# F28x7x_pie_ctrl_regs register map
Vendor: Texas Instruments
Peripheral module from a debugger description file (folder C2000).
Address unit: 16 bits
Registers are 16-bit, read-write, no defined reset value unless marked. A register's access mark holds for its fields unless they carry their own. Offsets are as the file gives them; lines under a group give offsets from that group; [hi:lo] are bit positions; {n}, {i} and the like mark numbered series; 'fields as' and 'values as' point back to an identical list; <NAME> marks a mode.

## PIE_CTRL_REGS
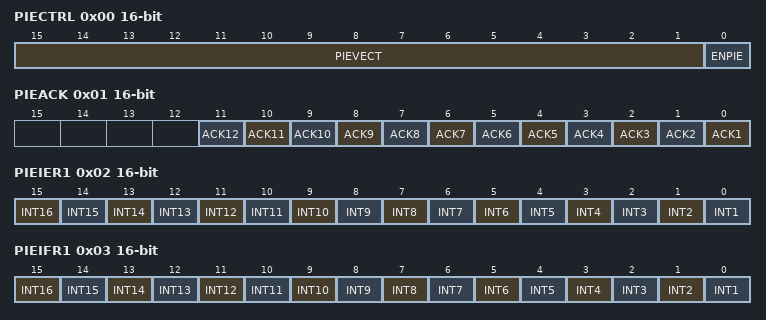
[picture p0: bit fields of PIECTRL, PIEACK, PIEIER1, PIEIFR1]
0x00 PIECTRL — Control Register
  [15:1] PIEVECT — PIE Vector Address
  [0] ENPIE — PIE Enable
0x01 PIEACK — Acknowledge Register
  [n-1] ACK{n} (n=1..12) — Acknowledge PIE Interrupt Group {n}
0x02 PIEIER1 — INT1 Group Enable Register
  [15] INT16 — Interrupt Enable for INT1.16
  [14] INT15 — Interrupt Enable for INT1.15
  [13] INT14 — Interrupt Enable for INT1.14
  [12] INT13 — Interrupt Enable for INT1.13
  [11] INT12 — Interrupt Enable for INT1.12
  [10] INT11 — Interrupt Enable for INT1.11
  [9] INT10 — Interrupt Enable for INT1.10
  [8] INT9 — Interrupt Enable for INT1.9
  [7] INT8 — Interrupt Enable for INT1.8
  [6] INT7 — Interrupt Enable for INT1.7
  [5] INT6 — Interrupt Enable for INT1.6
  [4] INT5 — Interrupt Enable for INT1.5
  [3] INT4 — Interrupt Enable for INT1.4
  [2] INT3 — Interrupt Enable for INT1.3
  [1] INT2 — Interrupt Enable for INT1.2
  [0] INT1 — Interrupt Enable for INT1.1
0x03 PIEIFR1 — INT1 Group Flag Register
  [15] INT16 — Interrupt Flag for INT1.16
  [14] INT15 — Interrupt Flag for INT1.15
  [13] INT14 — Interrupt Flag for INT1.14
  [12] INT13 — Interrupt Flag for INT1.13
  [11] INT12 — Interrupt Flag for INT1.12
  [10] INT11 — Interrupt Flag for INT1.11
  [9] INT10 — Interrupt Flag for INT1.10
  [8] INT9 — Interrupt Flag for INT1.9
  [7] INT8 — Interrupt Flag for INT1.8
  [6] INT7 — Interrupt Flag for INT1.7
  [5] INT6 — Interrupt Flag for INT1.6
  [4] INT5 — Interrupt Flag for INT1.5
  [3] INT4 — Interrupt Flag for INT1.4
  [2] INT3 — Interrupt Flag for INT1.3
  [1] INT2 — Interrupt Flag for INT1.2
  [0] INT1 — Interrupt Flag for INT1.1
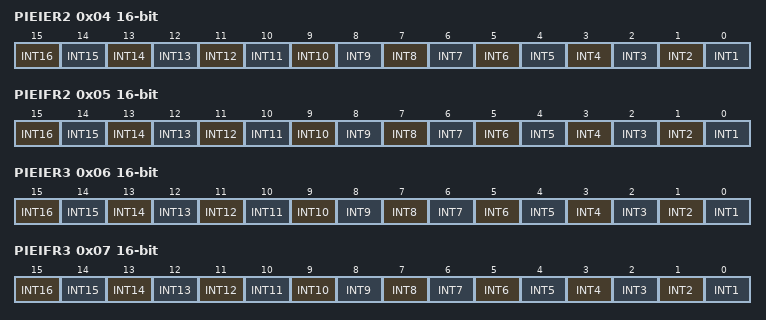
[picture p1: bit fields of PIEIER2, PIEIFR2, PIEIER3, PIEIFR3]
0x04 PIEIER2 — INT2 Group Enable Register
  [15] INT16 — Interrupt Enable for INT2.16
  [14] INT15 — Interrupt Enable for INT2.15
  [13] INT14 — Interrupt Enable for INT2.14
  [12] INT13 — Interrupt Enable for INT2.13
  [11] INT12 — Interrupt Enable for INT2.12
  [10] INT11 — Interrupt Enable for INT2.11
  [9] INT10 — Interrupt Enable for INT2.10
  [8] INT9 — Interrupt Enable for INT2.9
  [7] INT8 — Interrupt Enable for INT2.8
  [6] INT7 — Interrupt Enable for INT2.7
  [5] INT6 — Interrupt Enable for INT2.6
  [4] INT5 — Interrupt Enable for INT2.5
  [3] INT4 — Interrupt Enable for INT2.4
  [2] INT3 — Interrupt Enable for INT2.3
  [1] INT2 — Interrupt Enable for INT2.2
  [0] INT1 — Interrupt Enable for INT2.1
0x05 PIEIFR2 — INT2 Group Flag Register
  [15] INT16 — Interrupt Flag for INT2.16
  [14] INT15 — Interrupt Flag for INT2.15
  [13] INT14 — Interrupt Flag for INT2.14
  [12] INT13 — Interrupt Flag for INT2.13
  [11] INT12 — Interrupt Flag for INT2.12
  [10] INT11 — Interrupt Flag for INT2.11
  [9] INT10 — Interrupt Flag for INT2.10
  [8] INT9 — Interrupt Flag for INT2.9
  [7] INT8 — Interrupt Flag for INT2.8
  [6] INT7 — Interrupt Flag for INT2.7
  [5] INT6 — Interrupt Flag for INT2.6
  [4] INT5 — Interrupt Flag for INT2.5
  [3] INT4 — Interrupt Flag for INT2.4
  [2] INT3 — Interrupt Flag for INT2.3
  [1] INT2 — Interrupt Flag for INT2.2
  [0] INT1 — Interrupt Flag for INT2.1
0x06 PIEIER3 — INT3 Group Enable Register
  [15] INT16 — Interrupt Enable for INT3.16
  [14] INT15 — Interrupt Enable for INT3.15
  [13] INT14 — Interrupt Enable for INT3.14
  [12] INT13 — Interrupt Enable for INT3.13
  [11] INT12 — Interrupt Enable for INT3.12
  [10] INT11 — Interrupt Enable for INT3.11
  [9] INT10 — Interrupt Enable for INT3.10
  [8] INT9 — Interrupt Enable for INT3.9
  [7] INT8 — Interrupt Enable for INT3.8
  [6] INT7 — Interrupt Enable for INT3.7
  [5] INT6 — Interrupt Enable for INT3.6
  [4] INT5 — Interrupt Enable for INT3.5
  [3] INT4 — Interrupt Enable for INT3.4
  [2] INT3 — Interrupt Enable for INT3.3
  [1] INT2 — Interrupt Enable for INT3.2
  [0] INT1 — Interrupt Enable for INT3.1
0x07 PIEIFR3 — INT3 Group Flag Register
  [15] INT16 — Interrupt Flag for INT3.16
  [14] INT15 — Interrupt Flag for INT3.15
  [13] INT14 — Interrupt Flag for INT3.14
  [12] INT13 — Interrupt Flag for INT3.13
  [11] INT12 — Interrupt Flag for INT3.12
  [10] INT11 — Interrupt Flag for INT3.11
  [9] INT10 — Interrupt Flag for INT3.10
  [8] INT9 — Interrupt Flag for INT3.9
  [7] INT8 — Interrupt Flag for INT3.8
  [6] INT7 — Interrupt Flag for INT3.7
  [5] INT6 — Interrupt Flag for INT3.6
  [4] INT5 — Interrupt Flag for INT3.5
  [3] INT4 — Interrupt Flag for INT3.4
  [2] INT3 — Interrupt Flag for INT3.3
  [1] INT2 — Interrupt Flag for INT3.2
  [0] INT1 — Interrupt Flag for INT3.1
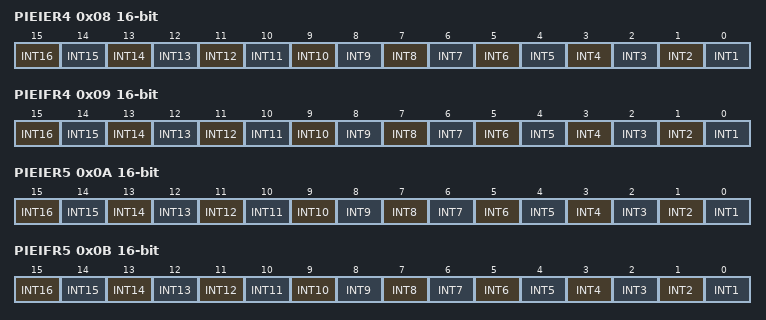
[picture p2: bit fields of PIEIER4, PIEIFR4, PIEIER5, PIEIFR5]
0x08 PIEIER4 — INT4 Group Enable Register
  [15] INT16 — Interrupt Enable for INT4.16
  [14] INT15 — Interrupt Enable for INT4.15
  [13] INT14 — Interrupt Enable for INT4.14
  [12] INT13 — Interrupt Enable for INT4.13
  [11] INT12 — Interrupt Enable for INT4.12
  [10] INT11 — Interrupt Enable for INT4.11
  [9] INT10 — Interrupt Enable for INT4.10
  [8] INT9 — Interrupt Enable for INT4.9
  [7] INT8 — Interrupt Enable for INT4.8
  [6] INT7 — Interrupt Enable for INT4.7
  [5] INT6 — Interrupt Enable for INT4.6
  [4] INT5 — Interrupt Enable for INT4.5
  [3] INT4 — Interrupt Enable for INT4.4
  [2] INT3 — Interrupt Enable for INT4.3
  [1] INT2 — Interrupt Enable for INT4.2
  [0] INT1 — Interrupt Enable for INT4.1
0x09 PIEIFR4 — INT4 Group Flag Register
  [15] INT16 — Interrupt Flag for INT4.16
  [14] INT15 — Interrupt Flag for INT4.15
  [13] INT14 — Interrupt Flag for INT4.14
  [12] INT13 — Interrupt Flag for INT4.13
  [11] INT12 — Interrupt Flag for INT4.12
  [10] INT11 — Interrupt Flag for INT4.11
  [9] INT10 — Interrupt Flag for INT4.10
  [8] INT9 — Interrupt Flag for INT4.9
  [7] INT8 — Interrupt Flag for INT4.8
  [6] INT7 — Interrupt Flag for INT4.7
  [5] INT6 — Interrupt Flag for INT4.6
  [4] INT5 — Interrupt Flag for INT4.5
  [3] INT4 — Interrupt Flag for INT4.4
  [2] INT3 — Interrupt Flag for INT4.3
  [1] INT2 — Interrupt Flag for INT4.2
  [0] INT1 — Interrupt Flag for INT4.1
0x0A PIEIER5 — INT5 Group Enable Register
  [15] INT16 — Interrupt Enable for INT5.16
  [14] INT15 — Interrupt Enable for INT5.15
  [13] INT14 — Interrupt Enable for INT5.14
  [12] INT13 — Interrupt Enable for INT5.13
  [11] INT12 — Interrupt Enable for INT5.12
  [10] INT11 — Interrupt Enable for INT5.11
  [9] INT10 — Interrupt Enable for INT5.10
  [8] INT9 — Interrupt Enable for INT5.9
  [7] INT8 — Interrupt Enable for INT5.8
  [6] INT7 — Interrupt Enable for INT5.7
  [5] INT6 — Interrupt Enable for INT5.6
  [4] INT5 — Interrupt Enable for INT5.5
  [3] INT4 — Interrupt Enable for INT5.4
  [2] INT3 — Interrupt Enable for INT5.3
  [1] INT2 — Interrupt Enable for INT5.2
  [0] INT1 — Interrupt Enable for INT5.1
0x0B PIEIFR5 — INT5 Group Flag Register
  [15] INT16 — Interrupt Flag for INT5.16
  [14] INT15 — Interrupt Flag for INT5.15
  [13] INT14 — Interrupt Flag for INT5.14
  [12] INT13 — Interrupt Flag for INT5.13
  [11] INT12 — Interrupt Flag for INT5.12
  [10] INT11 — Interrupt Flag for INT5.11
  [9] INT10 — Interrupt Flag for INT5.10
  [8] INT9 — Interrupt Flag for INT5.9
  [7] INT8 — Interrupt Flag for INT5.8
  [6] INT7 — Interrupt Flag for INT5.7
  [5] INT6 — Interrupt Flag for INT5.6
  [4] INT5 — Interrupt Flag for INT5.5
  [3] INT4 — Interrupt Flag for INT5.4
  [2] INT3 — Interrupt Flag for INT5.3
  [1] INT2 — Interrupt Flag for INT5.2
  [0] INT1 — Interrupt Flag for INT5.1
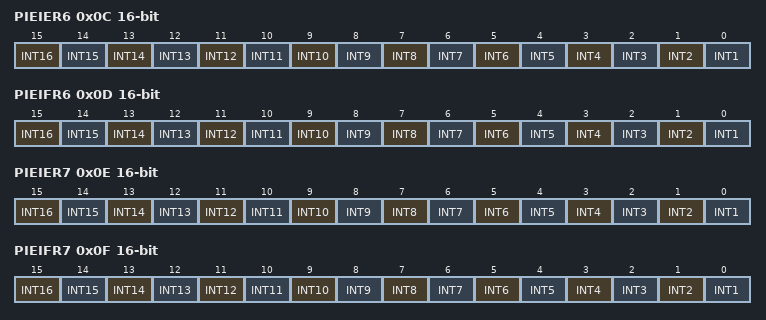
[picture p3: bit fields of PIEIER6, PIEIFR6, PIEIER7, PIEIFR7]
0x0C PIEIER6 — INT6 Group Enable Register
  [15] INT16 — Interrupt Enable for INT6.16
  [14] INT15 — Interrupt Enable for INT6.15
  [13] INT14 — Interrupt Enable for INT6.14
  [12] INT13 — Interrupt Enable for INT6.13
  [11] INT12 — Interrupt Enable for INT6.12
  [10] INT11 — Interrupt Enable for INT6.11
  [9] INT10 — Interrupt Enable for INT6.10
  [8] INT9 — Interrupt Enable for INT6.9
  [7] INT8 — Interrupt Enable for INT6.8
  [6] INT7 — Interrupt Enable for INT6.7
  [5] INT6 — Interrupt Enable for INT6.6
  [4] INT5 — Interrupt Enable for INT6.5
  [3] INT4 — Interrupt Enable for INT6.4
  [2] INT3 — Interrupt Enable for INT6.3
  [1] INT2 — Interrupt Enable for INT6.2
  [0] INT1 — Interrupt Enable for INT6.1
0x0D PIEIFR6 — INT6 Group Flag Register
  [15] INT16 — Interrupt Flag for INT6.16
  [14] INT15 — Interrupt Flag for INT6.15
  [13] INT14 — Interrupt Flag for INT6.14
  [12] INT13 — Interrupt Flag for INT6.13
  [11] INT12 — Interrupt Flag for INT6.12
  [10] INT11 — Interrupt Flag for INT6.11
  [9] INT10 — Interrupt Flag for INT6.10
  [8] INT9 — Interrupt Flag for INT6.9
  [7] INT8 — Interrupt Flag for INT6.8
  [6] INT7 — Interrupt Flag for INT6.7
  [5] INT6 — Interrupt Flag for INT6.6
  [4] INT5 — Interrupt Flag for INT6.5
  [3] INT4 — Interrupt Flag for INT6.4
  [2] INT3 — Interrupt Flag for INT6.3
  [1] INT2 — Interrupt Flag for INT6.2
  [0] INT1 — Interrupt Flag for INT6.1
0x0E PIEIER7 — INT7 Group Enable Register
  [15] INT16 — Interrupt Enable for INT7.16
  [14] INT15 — Interrupt Enable for INT7.15
  [13] INT14 — Interrupt Enable for INT7.14
  [12] INT13 — Interrupt Enable for INT7.13
  [11] INT12 — Interrupt Enable for INT7.12
  [10] INT11 — Interrupt Enable for INT7.11
  [9] INT10 — Interrupt Enable for INT7.10
  [8] INT9 — Interrupt Enable for INT7.9
  [7] INT8 — Interrupt Enable for INT7.8
  [6] INT7 — Interrupt Enable for INT7.7
  [5] INT6 — Interrupt Enable for INT7.6
  [4] INT5 — Interrupt Enable for INT7.5
  [3] INT4 — Interrupt Enable for INT7.4
  [2] INT3 — Interrupt Enable for INT7.3
  [1] INT2 — Interrupt Enable for INT7.2
  [0] INT1 — Interrupt Enable for INT7.1
0x0F PIEIFR7 — INT7 Group Flag Register
  [15] INT16 — Interrupt Flag for INT7.16
  [14] INT15 — Interrupt Flag for INT7.15
  [13] INT14 — Interrupt Flag for INT7.14
  [12] INT13 — Interrupt Flag for INT7.13
  [11] INT12 — Interrupt Flag for INT7.12
  [10] INT11 — Interrupt Flag for INT7.11
  [9] INT10 — Interrupt Flag for INT7.10
  [8] INT9 — Interrupt Flag for INT7.9
  [7] INT8 — Interrupt Flag for INT7.8
  [6] INT7 — Interrupt Flag for INT7.7
  [5] INT6 — Interrupt Flag for INT7.6
  [4] INT5 — Interrupt Flag for INT7.5
  [3] INT4 — Interrupt Flag for INT7.4
  [2] INT3 — Interrupt Flag for INT7.3
  [1] INT2 — Interrupt Flag for INT7.2
  [0] INT1 — Interrupt Flag for INT7.1
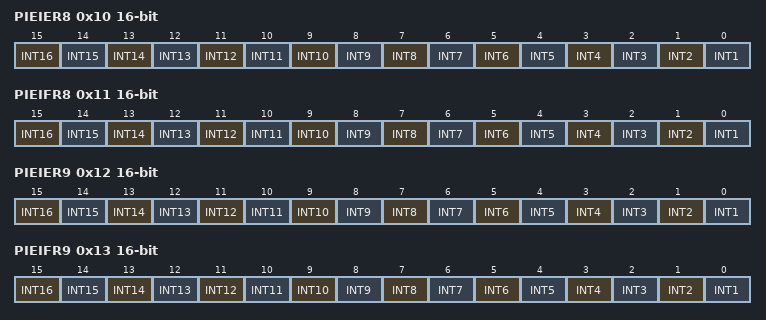
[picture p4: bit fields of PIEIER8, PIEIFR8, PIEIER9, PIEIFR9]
0x10 PIEIER8 — INT8 Group Enable Register
  [15] INT16 — Interrupt Enable for INT8.16
  [14] INT15 — Interrupt Enable for INT8.15
  [13] INT14 — Interrupt Enable for INT8.14
  [12] INT13 — Interrupt Enable for INT8.13
  [11] INT12 — Interrupt Enable for INT8.12
  [10] INT11 — Interrupt Enable for INT8.11
  [9] INT10 — Interrupt Enable for INT8.10
  [8] INT9 — Interrupt Enable for INT8.9
  [7] INT8 — Interrupt Enable for INT8.8
  [6] INT7 — Interrupt Enable for INT8.7
  [5] INT6 — Interrupt Enable for INT8.6
  [4] INT5 — Interrupt Enable for INT8.5
  [3] INT4 — Interrupt Enable for INT8.4
  [2] INT3 — Interrupt Enable for INT8.3
  [1] INT2 — Interrupt Enable for INT8.2
  [0] INT1 — Interrupt Enable for INT8.1
0x11 PIEIFR8 — INT8 Group Flag Register
  [15] INT16 — Interrupt Flag for INT8.16
  [14] INT15 — Interrupt Flag for INT8.15
  [13] INT14 — Interrupt Flag for INT8.14
  [12] INT13 — Interrupt Flag for INT8.13
  [11] INT12 — Interrupt Flag for INT8.12
  [10] INT11 — Interrupt Flag for INT8.11
  [9] INT10 — Interrupt Flag for INT8.10
  [8] INT9 — Interrupt Flag for INT8.9
  [7] INT8 — Interrupt Flag for INT8.8
  [6] INT7 — Interrupt Flag for INT8.7
  [5] INT6 — Interrupt Flag for INT8.6
  [4] INT5 — Interrupt Flag for INT8.5
  [3] INT4 — Interrupt Flag for INT8.4
  [2] INT3 — Interrupt Flag for INT8.3
  [1] INT2 — Interrupt Flag for INT8.2
  [0] INT1 — Interrupt Flag for INT8.1
0x12 PIEIER9 — INT9 Group Enable Register
  [15] INT16 — Interrupt Enable for INT9.16
  [14] INT15 — Interrupt Enable for INT9.15
  [13] INT14 — Interrupt Enable for INT9.14
  [12] INT13 — Interrupt Enable for INT9.13
  [11] INT12 — Interrupt Enable for INT9.12
  [10] INT11 — Interrupt Enable for INT9.11
  [9] INT10 — Interrupt Enable for INT9.10
  [8] INT9 — Interrupt Enable for INT9.9
  [7] INT8 — Interrupt Enable for INT9.8
  [6] INT7 — Interrupt Enable for INT9.7
  [5] INT6 — Interrupt Enable for INT9.6
  [4] INT5 — Interrupt Enable for INT9.5
  [3] INT4 — Interrupt Enable for INT9.4
  [2] INT3 — Interrupt Enable for INT9.3
  [1] INT2 — Interrupt Enable for INT9.2
  [0] INT1 — Interrupt Enable for INT9.1
0x13 PIEIFR9 — INT9 Group Flag Register
  [15] INT16 — Interrupt Flag for INT9.16
  [14] INT15 — Interrupt Flag for INT9.15
  [13] INT14 — Interrupt Flag for INT9.14
  [12] INT13 — Interrupt Flag for INT9.13
  [11] INT12 — Interrupt Flag for INT9.12
  [10] INT11 — Interrupt Flag for INT9.11
  [9] INT10 — Interrupt Flag for INT9.10
  [8] INT9 — Interrupt Flag for INT9.9
  [7] INT8 — Interrupt Flag for INT9.8
  [6] INT7 — Interrupt Flag for INT9.7
  [5] INT6 — Interrupt Flag for INT9.6
  [4] INT5 — Interrupt Flag for INT9.5
  [3] INT4 — Interrupt Flag for INT9.4
  [2] INT3 — Interrupt Flag for INT9.3
  [1] INT2 — Interrupt Flag for INT9.2
  [0] INT1 — Interrupt Flag for INT9.1
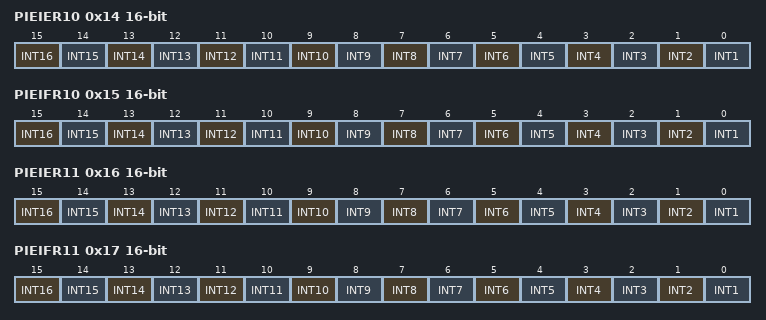
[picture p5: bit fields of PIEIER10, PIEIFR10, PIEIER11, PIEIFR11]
0x14 PIEIER10 — INT10 Group Enable Register
  [15] INT16 — Interrupt Enable for INT10.16
  [14] INT15 — Interrupt Enable for INT10.15
  [13] INT14 — Interrupt Enable for INT10.14
  [12] INT13 — Interrupt Enable for INT10.13
  [11] INT12 — Interrupt Enable for INT10.12
  [10] INT11 — Interrupt Enable for INT10.11
  [9] INT10 — Interrupt Enable for INT10.10
  [8] INT9 — Interrupt Enable for INT10.9
  [7] INT8 — Interrupt Enable for INT10.8
  [6] INT7 — Interrupt Enable for INT10.7
  [5] INT6 — Interrupt Enable for INT10.6
  [4] INT5 — Interrupt Enable for INT10.5
  [3] INT4 — Interrupt Enable for INT10.4
  [2] INT3 — Interrupt Enable for INT10.3
  [1] INT2 — Interrupt Enable for INT10.2
  [0] INT1 — Interrupt Enable for INT10.1
0x15 PIEIFR10 — INT10 Group Flag Register
  [15] INT16 — Interrupt Flag for INT10.16
  [14] INT15 — Interrupt Flag for INT10.15
  [13] INT14 — Interrupt Flag for INT10.14
  [12] INT13 — Interrupt Flag for INT10.13
  [11] INT12 — Interrupt Flag for INT10.12
  [10] INT11 — Interrupt Flag for INT10.11
  [9] INT10 — Interrupt Flag for INT10.10
  [8] INT9 — Interrupt Flag for INT10.9
  [7] INT8 — Interrupt Flag for INT10.8
  [6] INT7 — Interrupt Flag for INT10.7
  [5] INT6 — Interrupt Flag for INT10.6
  [4] INT5 — Interrupt Flag for INT10.5
  [3] INT4 — Interrupt Flag for INT10.4
  [2] INT3 — Interrupt Flag for INT10.3
  [1] INT2 — Interrupt Flag for INT10.2
  [0] INT1 — Interrupt Flag for INT10.1
0x16 PIEIER11 — INT11 Group Enable Register
  [15] INT16 — Interrupt Enable for INT11.16
  [14] INT15 — Interrupt Enable for INT11.15
  [13] INT14 — Interrupt Enable for INT11.14
  [12] INT13 — Interrupt Enable for INT11.13
  [11] INT12 — Interrupt Enable for INT11.12
  [10] INT11 — Interrupt Enable for INT11.11
  [9] INT10 — Interrupt Enable for INT11.10
  [8] INT9 — Interrupt Enable for INT11.9
  [7] INT8 — Interrupt Enable for INT11.8
  [6] INT7 — Interrupt Enable for INT11.7
  [5] INT6 — Interrupt Enable for INT11.6
  [4] INT5 — Interrupt Enable for INT11.5
  [3] INT4 — Interrupt Enable for INT11.4
  [2] INT3 — Interrupt Enable for INT11.3
  [1] INT2 — Interrupt Enable for INT11.2
  [0] INT1 — Interrupt Enable for INT11.1
0x17 PIEIFR11 — INT11 Group Flag Register
  [15] INT16 — Interrupt Flag for INT11.16
  [14] INT15 — Interrupt Flag for INT11.15
  [13] INT14 — Interrupt Flag for INT11.14
  [12] INT13 — Interrupt Flag for INT11.13
  [11] INT12 — Interrupt Flag for INT11.12
  [10] INT11 — Interrupt Flag for INT11.11
  [9] INT10 — Interrupt Flag for INT11.10
  [8] INT9 — Interrupt Flag for INT11.9
  [7] INT8 — Interrupt Flag for INT11.8
  [6] INT7 — Interrupt Flag for INT11.7
  [5] INT6 — Interrupt Flag for INT11.6
  [4] INT5 — Interrupt Flag for INT11.5
  [3] INT4 — Interrupt Flag for INT11.4
  [2] INT3 — Interrupt Flag for INT11.3
  [1] INT2 — Interrupt Flag for INT11.2
  [0] INT1 — Interrupt Flag for INT11.1
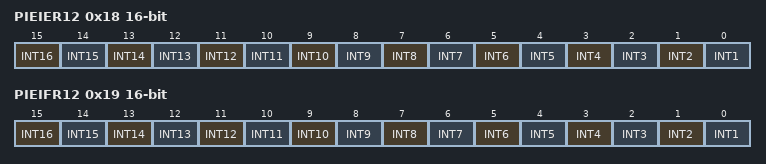
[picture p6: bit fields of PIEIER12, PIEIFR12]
0x18 PIEIER12 — INT12 Group Enable Register
  [15] INT16 — Interrupt Enable for INT12.16
  [14] INT15 — Interrupt Enable for INT12.15
  [13] INT14 — Interrupt Enable for INT12.14
  [12] INT13 — Interrupt Enable for INT12.13
  [11] INT12 — Interrupt Enable for INT12.12
  [10] INT11 — Interrupt Enable for INT12.11
  [9] INT10 — Interrupt Enable for INT12.10
  [8] INT9 — Interrupt Enable for INT12.9
  [7] INT8 — Interrupt Enable for INT12.8
  [6] INT7 — Interrupt Enable for INT12.7
  [5] INT6 — Interrupt Enable for INT12.6
  [4] INT5 — Interrupt Enable for INT12.5
  [3] INT4 — Interrupt Enable for INT12.4
  [2] INT3 — Interrupt Enable for INT12.3
  [1] INT2 — Interrupt Enable for INT12.2
  [0] INT1 — Interrupt Enable for INT12.1
0x19 PIEIFR12 — INT12 Group Flag Register
  [15] INT16 — Interrupt Flag for INT12.16
  [14] INT15 — Interrupt Flag for INT12.15
  [13] INT14 — Interrupt Flag for INT12.14
  [12] INT13 — Interrupt Flag for INT12.13
  [11] INT12 — Interrupt Flag for INT12.12
  [10] INT11 — Interrupt Flag for INT12.11
  [9] INT10 — Interrupt Flag for INT12.10
  [8] INT9 — Interrupt Flag for INT12.9
  [7] INT8 — Interrupt Flag for INT12.8
  [6] INT7 — Interrupt Flag for INT12.7
  [5] INT6 — Interrupt Flag for INT12.6
  [4] INT5 — Interrupt Flag for INT12.5
  [3] INT4 — Interrupt Flag for INT12.4
  [2] INT3 — Interrupt Flag for INT12.3
  [1] INT2 — Interrupt Flag for INT12.2
  [0] INT1 — Interrupt Flag for INT12.1
